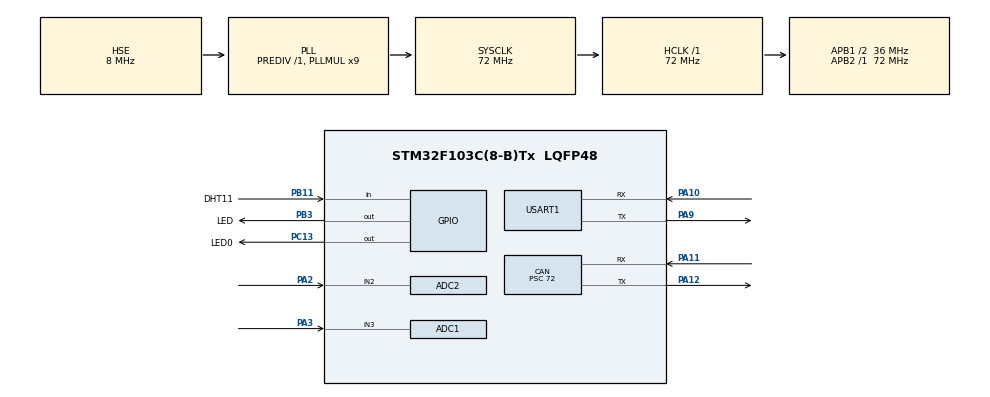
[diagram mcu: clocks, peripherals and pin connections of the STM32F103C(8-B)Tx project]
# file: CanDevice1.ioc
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ADC1.Channel-3\#ChannelRegularConversion=ADC_CHANNEL_3
ADC1.NbrOfConversionFlag=1
ADC1.Rank-3\#ChannelRegularConversion=1
ADC1.SamplingTime-3\#ChannelRegularConversion=ADC_SAMPLETIME_1CYCLE_5
ADC1.master=1
ADC2.Channel-1\#ChannelRegularConversion=ADC_CHANNEL_2
ADC2.NbrOfConversionFlag=1
ADC2.Rank-1\#ChannelRegularConversion=1
ADC2.SamplingTime-1\#ChannelRegularConversion=ADC_SAMPLETIME_1CYCLE_5
CAN.BS1=CAN_BS1_8TQ
CAN.CalculateBaudRate=50000
CAN.CalculateTimeBit=20000
CAN.CalculateTimeQuantum=2000.0
CAN.Mode=CAN_MODE_NORMAL
CAN.Prescaler=72
CAN.SJW=CAN_SJW_2TQ
FREERTOS.Queues01=EnvironmentQueue,1,Environment_Data_t,0,Dynamic,NULL,NULL
FREERTOS.Tasks01=EnvironmentTask,24,128,StartEnvironmentTask,As weak,NULL,Dynamic,NULL,NULL;CANTask,40,256,StartCANTask,As weak,NULL,Dynamic,NULL,NULL
FREERTOS.configTOTAL_HEAP_SIZE=5000
Mcu.Family=STM32F1
Mcu.Name=STM32F103C(8-B)Tx
Mcu.Package=LQFP48
NVIC.PriorityGroup=NVIC_PRIORITYGROUP_4
NVIC.TIM3_IRQn=true\:15\:0\:false\:false\:true\:false\:false\:true\:true
NVIC.TimeBase=TIM3_IRQn
NVIC.TimeBaseIP=TIM3
PA10.Mode=Asynchronous
PA10.Signal=USART1_RX
PA11.Mode=CAN_Activate
PA11.Signal=CAN_RX
PA12.Mode=CAN_Activate
PA12.Signal=CAN_TX
PA13.Mode=Serial_Wire
PA13.Signal=SYS_JTMS-SWDIO
PA14.Mode=Serial_Wire
PA14.Signal=SYS_JTCK-SWCLK
PA2.Signal=ADCx_IN2
PA3.Signal=ADCx_IN3
PA9.Mode=Asynchronous
PA9.Signal=USART1_TX
PB11.GPIO_Label=DHT11
PB11.Signal=GPIO_Input
PB3.GPIO_Label=LED
PB3.GPIO_ModeDefaultOutputPP=GPIO_MODE_OUTPUT_PP
PB3.GPIO_PuPd=GPIO_PULLDOWN
PB3.Signal=GPIO_Output
PC13-TAMPER-RTC.GPIO_Label=LED0
PC13-TAMPER-RTC.Signal=GPIO_Output
PD0-OSC_IN.Mode=HSE-External-Oscillator
PD0-OSC_IN.Signal=RCC_OSC_IN
PD1-OSC_OUT.Mode=HSE-External-Oscillator
PD1-OSC_OUT.Signal=RCC_OSC_OUT
ProjectManager.HeapSize=0x200
ProjectManager.StackSize=0x400
ProjectManager.TargetToolchain=CMake
RCC.ADCPresc=RCC_ADCPCLK2_DIV6
RCC.AHBFreq_Value=72000000
RCC.APB1CLKDivider=RCC_HCLK_DIV2
RCC.APB1Freq_Value=36000000
RCC.APB1TimFreq_Value=72000000
RCC.APB2Freq_Value=72000000
RCC.APB2TimFreq_Value=72000000
RCC.HCLKFreq_Value=72000000
RCC.PLLMUL=RCC_PLL_MUL9
RCC.PLLSourceVirtual=RCC_PLLSOURCE_HSE
RCC.SYSCLKFreq_VALUE=72000000
RCC.SYSCLKSource=RCC_SYSCLKSOURCE_PLLCLK
RCC.USBFreq_Value=72000000
SH.ADCx_IN2.0=ADC2_IN2,IN2
SH.ADCx_IN3.0=ADC1_IN3,IN3
USART1.VirtualMode=VM_ASYNC
VP_FREERTOS_VS_CMSIS_V2.Mode=CMSIS_V2
VP_SYS_VS_tim3.Mode=TIM3
board=custom

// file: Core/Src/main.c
/* USER CODE BEGIN Header */
/**
 ******************************************************************************
 * @file           : main.c
 * @brief          : Main program body
 ******************************************************************************
 * @attention
 *
 * Copyright (c) 2026 STMicroelectronics.
 * All rights reserved.
 *
 * This software is licensed under terms that can be found in the LICENSE file
 * in the root directory of this software component.
 * If no LICENSE file comes with this software, it is provided AS-IS.
 *
 ******************************************************************************
 */
/* USER CODE END Header */
#include "main.h"
#include "cmsis_os.h"
#include "adc.h"
#include "can.h"
#include "usart.h"
#include "gpio.h"

/* USER CODE BEGIN Includes */
#include <string.h>
#include "DHT11.h"
/* USER CODE END Includes */

void SystemClock_Config(void);
void MX_FREERTOS_Init(void);

int main(void)
{

  /* USER CODE BEGIN 1 */
  __disable_irq();
  SCB->VTOR = 0x8004000;
  __enable_irq();
  /* USER CODE END 1 */

  /* MCU Configuration--------------------------------------------------------*/

  /* Reset of all peripherals, Initializes the Flash interface and the Systick. */
  HAL_Init();

  /* Configure the system clock */
  SystemClock_Config();

  /* Initialize all configured peripherals */
  MX_GPIO_Init();
  MX_CAN_Init();
  MX_USART1_UART_Init();
  MX_ADC1_Init();
  MX_ADC2_Init();
  /* USER CODE BEGIN 2 */
  HAL_GPIO_WritePin(LED0_GPIO_Port, LED0_Pin, GPIO_PIN_RESET);

  /* USER CODE END 2 */

  /* Init scheduler */
  osKernelInitialize();  /* Call init function for freertos objects (in cmsis_os2.c) */
  MX_FREERTOS_Init();

  /* Start scheduler */
  osKernelStart();

  /* We should never get here as control is now taken by the scheduler */

  /* Infinite loop */
  while (1) {

  }
}

void SystemClock_Config(void)
{
  RCC_OscInitTypeDef RCC_OscInitStruct = {0};
  RCC_ClkInitTypeDef RCC_ClkInitStruct = {0};
  RCC_PeriphCLKInitTypeDef PeriphClkInit = {0};

  /** Initializes the RCC Oscillators according to the specified parameters
  * in the RCC_OscInitTypeDef structure.
  */
  RCC_OscInitStruct.OscillatorType = RCC_OSCILLATORTYPE_HSE;
  RCC_OscInitStruct.HSEState = RCC_HSE_ON;
  RCC_OscInitStruct.HSEPredivValue = RCC_HSE_PREDIV_DIV1;
  RCC_OscInitStruct.HSIState = RCC_HSI_ON;
  RCC_OscInitStruct.PLL.PLLState = RCC_PLL_ON;
  RCC_OscInitStruct.PLL.PLLSource = RCC_PLLSOURCE_HSE;
  RCC_OscInitStruct.PLL.PLLMUL = RCC_PLL_MUL9;
  if (HAL_RCC_OscConfig(&RCC_OscInitStruct) != HAL_OK)
  {
    Error_Handler();
  }

  /** Initializes the CPU, AHB and APB buses clocks
  */
  RCC_ClkInitStruct.ClockType = RCC_CLOCKTYPE_HCLK|RCC_CLOCKTYPE_SYSCLK
                              |RCC_CLOCKTYPE_PCLK1|RCC_CLOCKTYPE_PCLK2;
  RCC_ClkInitStruct.SYSCLKSource = RCC_SYSCLKSOURCE_PLLCLK;
  RCC_ClkInitStruct.AHBCLKDivider = RCC_SYSCLK_DIV1;
  RCC_ClkInitStruct.APB1CLKDivider = RCC_HCLK_DIV2;
  RCC_ClkInitStruct.APB2CLKDivider = RCC_HCLK_DIV1;

  if (HAL_RCC_ClockConfig(&RCC_ClkInitStruct, FLASH_LATENCY_2) != HAL_OK)
  {
    Error_Handler();
  }
  PeriphClkInit.PeriphClockSelection = RCC_PERIPHCLK_ADC;
  PeriphClkInit.AdcClockSelection = RCC_ADCPCLK2_DIV6;
  if (HAL_RCCEx_PeriphCLKConfig(&PeriphClkInit) != HAL_OK)
  {
    Error_Handler();
  }
}

void HAL_TIM_PeriodElapsedCallback(TIM_HandleTypeDef *htim)
{
  if (htim->Instance == TIM3)
  {
    HAL_IncTick();
  }
}

void Error_Handler(void)
{
  __disable_irq();
  while (1) {
  }
}
#ifdef USE_FULL_ASSERT
/**
  * @brief  Reports the name of the source file and the source line number
  *         where the assert_param error has occurred.
  * @param  file: pointer to the source file name
  * @param  line: assert_param error line source number
  * @retval None
  */
void assert_failed(uint8_t *file, uint32_t line)
{
  /* USER CODE BEGIN 6 */
  /* User can add his own implementation to report the file name and line
     number, ex: printf("Wrong parameters value: file %s on line %d\r\n", file,
     line) */
  /* USER CODE END 6 */
}
#endif /* USE_FULL_ASSERT */

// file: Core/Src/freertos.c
/* USER CODE BEGIN Header */
/**
  ******************************************************************************
  * File Name          : freertos.c
  * Description        : Code for freertos applications
  ******************************************************************************
  * @attention
  *
  * Copyright (c) 2026 STMicroelectronics.
  * All rights reserved.
  *
  * This software is licensed under terms that can be found in the LICENSE file
  * in the root directory of this software component.
  * If no LICENSE file comes with this software, it is provided AS-IS.
  *
  ******************************************************************************
  */
/* USER CODE END Header */

#include "FreeRTOS.h"
#include "task.h"
#include "main.h"
#include "cmsis_os.h"

/* USER CODE BEGIN Includes */
#include "Environment.h"
/* USER CODE END Includes */

/* Definitions for EnvironmentTask */
osThreadId_t EnvironmentTaskHandle;
const osThreadAttr_t EnvironmentTask_attributes = {
  .name = "EnvironmentTask",
  .stack_size = 128 * 4,
  .priority = (osPriority_t) osPriorityNormal,
};
/* Definitions for CANTask */
osThreadId_t CANTaskHandle;
const osThreadAttr_t CANTask_attributes = {
  .name = "CANTask",
  .stack_size = 256 * 4,
  .priority = (osPriority_t) osPriorityHigh,
};
/* Definitions for EnvironmentQueue */
osMessageQueueId_t EnvironmentQueueHandle;
const osMessageQueueAttr_t EnvironmentQueue_attributes = {
  .name = "EnvironmentQueue"
};

void StartEnvironmentTask(void *argument);
void StartCANTask(void *argument);

void MX_FREERTOS_Init(void); /* (MISRA C 2004 rule 8.1) */

void MX_FREERTOS_Init(void) {

  /* Create the queue(s) */
  /* creation of EnvironmentQueue */
  EnvironmentQueueHandle = osMessageQueueNew (1, sizeof(Environment_Data_t), &EnvironmentQueue_attributes);

  /* Create the thread(s) */
  /* creation of EnvironmentTask */
  EnvironmentTaskHandle = osThreadNew(StartEnvironmentTask, NULL, &EnvironmentTask_attributes);

  /* creation of CANTask */
  CANTaskHandle = osThreadNew(StartCANTask, NULL, &CANTask_attributes);

}

__weak void StartEnvironmentTask(void *argument)
{
  for(;;)
  {
    osDelay(1);
  }
}

__weak void StartCANTask(void *argument)
{
  for(;;)
  {
    osDelay(1);
  }
}
